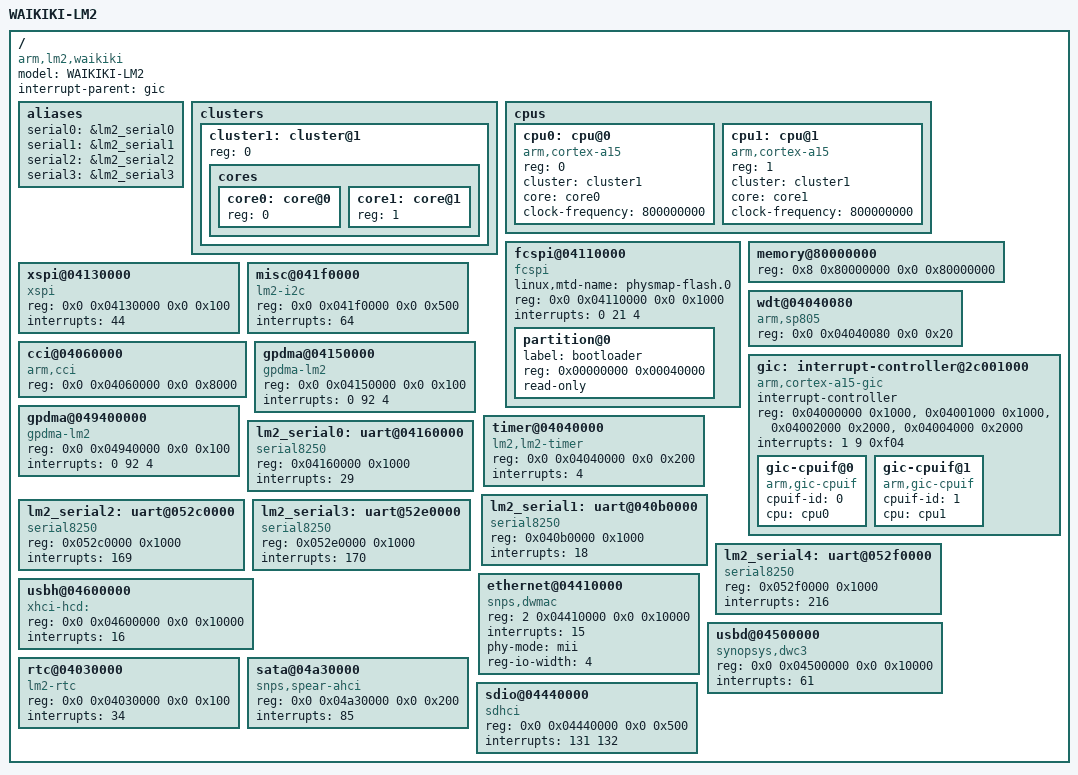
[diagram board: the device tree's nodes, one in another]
/*
 * FujiXerox
 *
 * Waikiki  A15x2 A7x1 M3x2
 * LM 2 Multi core  (CA15_A7)
 *
 *
 */

/dts-v1/;

/ {
	model = "WAIKIKI-LM2";
	compatible = "arm,lm2,waikiki", "arm,lm2";
	interrupt-parent = <&gic>;
	/* This section address is 40bit addressing */
	#address-cells = <2>;
	#size-cells = <2>;

	aliases {
		serial0 = &lm2_serial0;
		serial1 = &lm2_serial1;
		serial2 = &lm2_serial2;
		serial3 = &lm2_serial3;
	};

	clusters {
		#address-cells = <1>;
		#size-cells = <0>;

		cluster1: cluster@1 {
			reg = <0>;
			cores {
				#address-cells = <1>;
				#size-cells = <0>;

				core0: core@0 {
					reg = <0>;
				};

				core1: core@1 {
					reg = <1>;
				};

			};
		};

	};

	cpus {
		#address-cells = <1>;
		#size-cells = <0>;

		cpu0: cpu@0 {
			device_type = "cpu";
			compatible = "arm,cortex-a15";
			reg = <0>;
			cluster = <&cluster1>;
			core = <&core0>;
			clock-frequency = <800000000>;
		};

		cpu1: cpu@1 {
			device_type = "cpu";
			compatible = "arm,cortex-a15";
			reg = <1>;
			cluster = <&cluster1>;
			core = <&core1>;
			clock-frequency = <800000000>;
		};
	};

	fcspi@04110000{
		compatible = "fcspi";
		linux,mtd-name = "physmap-flash.0";
		reg = <0x0 0x04110000 0x0 0x1000>;
		interrupts = <0 21 4>;
		#address-cells = <1>;
		#size-cells = <1>;
 
		partition@0 {
			label = "bootloader";
			reg = <0x00000000 0x00040000>;
			read-only;
                };
	};

	memory@80000000 {
		device_type = "memory";
		reg = <0x8 0x80000000 0x0 0x80000000>;
	};

	xspi@04130000 {
		compatible = "xspi";
		reg = <0x0 0x04130000 0x0 0x100>;
		interrupts = <44>;
	};

	misc@041f0000 {
		compatible = "lm2-i2c";
		reg = <0x0 0x041f0000 0x0 0x500>;
		interrupts = <64>;
	};

	wdt@04040080 {
		compatible = "arm,sp805", "arm,primecell";
		reg = <0x0 0x04040080 0x0 0x20>;
	};

	cci@04060000 {
		compatible = "arm,cci";
		reg = <0x0 0x04060000 0x0 0x8000>;
	};

	gic: interrupt-controller@2c001000 {
		compatible = "arm,cortex-a15-gic", "arm,cortex-a9-gic";
		#interrupt-cells = <3>;
		#address-cells = <0>;
		interrupt-controller;
		reg = <0x04000000 0x1000>,
		      <0x04001000 0x1000>,
		      <0x04002000 0x2000>,
		      <0x04004000 0x2000>;
		interrupts = <1 9 0xf04>;

		gic-cpuif@0 {
			compatible = "arm,gic-cpuif";
			cpuif-id = <0>;
			cpu = <&cpu0>;
		};
		gic-cpuif@1 {
			compatible = "arm,gic-cpuif";
			cpuif-id = <1>;
			cpu = <&cpu1>;
		};
	};

	gpdma@04150000 {
		compatible = "gpdma-lm2";
		reg = <0x0 0x04150000 0x0 0x100>;
		interrupts = <0 92 4>;
	};

	gpdma@049400000 {
		compatible = "gpdma-lm2";
		reg = <0x0 0x04940000 0x0 0x100>;
		interrupts = <0 92 4>;
	};

	timer@04040000 {
		compatible = "lm2,lm2-timer";
		reg = <0x0 0x04040000 0x0 0x200>;
		interrupts = <4>;
	};

	lm2_serial0: uart@04160000 {
		compatible = "serial8250";
		reg = <0x04160000 0x1000>;
		interrupts = <29>;
	};

	lm2_serial1: uart@040b0000 {
		compatible = "serial8250";
		reg = <0x040b0000 0x1000>;
		interrupts = <18>;
	};

	lm2_serial2: uart@052c0000 {
		compatible = "serial8250";
		reg = <0x052c0000 0x1000>;
		interrupts = <169>;
	};

	lm2_serial3: uart@52e0000 {
   		compatible = "serial8250";
		reg = <0x052e0000 0x1000>;
		interrupts = <170>;
	};

	lm2_serial4: uart@052f0000 {
		compatible = "serial8250";
		reg = <0x052f0000 0x1000>;
		interrupts = <216>;
	};

	ethernet@04410000 {
		compatible = "snps,dwmac";
		reg = <2 0x04410000 0x0 0x10000>;
		interrupts = <15>;
		phy-mode = "mii";
		reg-io-width = <4>;
	};

	usbh@04600000 {
		compatible = "xhci-hcd:";
		reg = <0x0 0x04600000 0x0 0x10000>;
		interrupts = <16>;
	};

	usbd@04500000 {
		compatible = "synopsys,dwc3","dwc3";
		reg = <0x0 0x04500000 0x0 0x10000>;
		interrupts = <61>;
	};

	rtc@04030000 {
		compatible = "lm2-rtc";
		reg = <0x0 0x04030000 0x0 0x100>;
		interrupts = <34>;
	};

	sata@04a30000 {
		compatible = "snps,spear-ahci","ahci";
		reg = <0x0 0x04a30000 0x0 0x200>;
		interrupts = <85>;
	};

	sdio@04440000 {
		compatible = "sdhci";
		reg = <0x0 0x04440000 0x0 0x500>;
		interrupts = <131 132>;
	};
};
